# STM32F103_min register map
Minimal CMSIS-SVD subset for AI MCU debug context tests.
CPU: CM3 r1p1, little endian, MPU, no FPU, 4 interrupt priority bits
Registers are 32-bit, read-write, reset 0x0 unless marked. A register's access mark holds for its fields unless they carry their own. Offsets are from the block's base; lines under a group give offsets from that group; [hi:lo] are bit positions; {n}, {i} and the like mark numbered series; 'fields as' and 'values as' point back to an identical list; <NAME> marks a mode.

## Memory map
0x40011000 GPIOC — General-purpose IO port C.
0x40021000 RCC — Reset and clock control.

## RCC — Reset and clock control.
Base 0x40021000
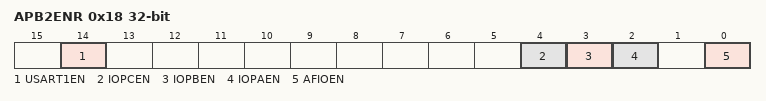
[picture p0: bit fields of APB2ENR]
0x18 APB2ENR — APB2 peripheral clock enable register.
  [14] USART1EN — USART1 clock enable.
  [4] IOPCEN — IO port C clock enable.
  [3] IOPBEN — IO port B clock enable.
  [2] IOPAEN — IO port A clock enable.
  [0] AFIOEN — Alternate function IO clock enable.

## GPIOC — General-purpose IO port C.
Base 0x40011000
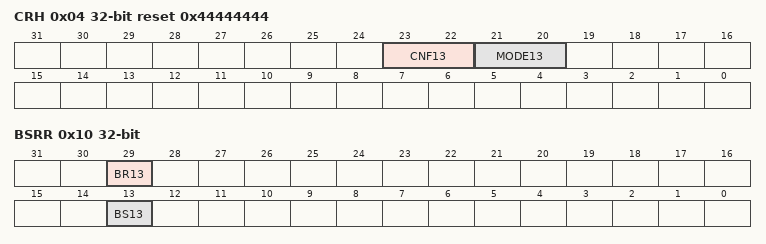
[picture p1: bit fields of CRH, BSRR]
0x04 CRH reset 0x44444444 — Port configuration register high.
  [23:22] CNF13 — Port x configuration bits for pin 13.
  [21:20] MODE13 — Port x mode bits for pin 13.
0x08 IDR ro — Port input data register.
  [13] IDR13 — Port input data for pin 13.
0x0C ODR — Port output data register.
  [13] ODR13 — Port output data for pin 13.
0x10 BSRR wo — Port bit set/reset register. Some fields are write 1 to clear/reset style.
  [29] BR13 — Reset bit for pin 13; write 1 to clear/reset output bit.
  [13] BS13 — Set bit for pin 13.
0x14 BRR wo — Port bit reset register.
  [13] BR13 — Reset bit for pin 13.
